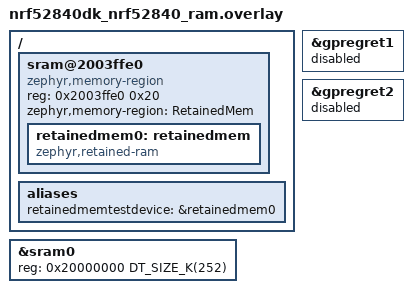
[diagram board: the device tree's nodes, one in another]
/ {
	sram@2003ffe0 {
		compatible = "zephyr,memory-region", "mmio-sram";
		reg = <0x2003ffe0 0x20>;
		ranges = <0x0 0x2003ffe0 0x20>;
		zephyr,memory-region = "RetainedMem";
		status = "okay";
		#address-cells = <1>;
		#size-cells = <1>;

		retainedmem0: retainedmem {
			compatible = "zephyr,retained-ram";
			status = "okay";
			ranges;
			#address-cells = <1>;
			#size-cells = <1>;
		};
	};

	aliases {
		retainedmemtestdevice = &retainedmem0;
	};
};

&gpregret1 {
	status = "disabled";
};

&gpregret2 {
	status = "disabled";
};

&sram0 {
	reg = <0x20000000 DT_SIZE_K(252)>;
};
